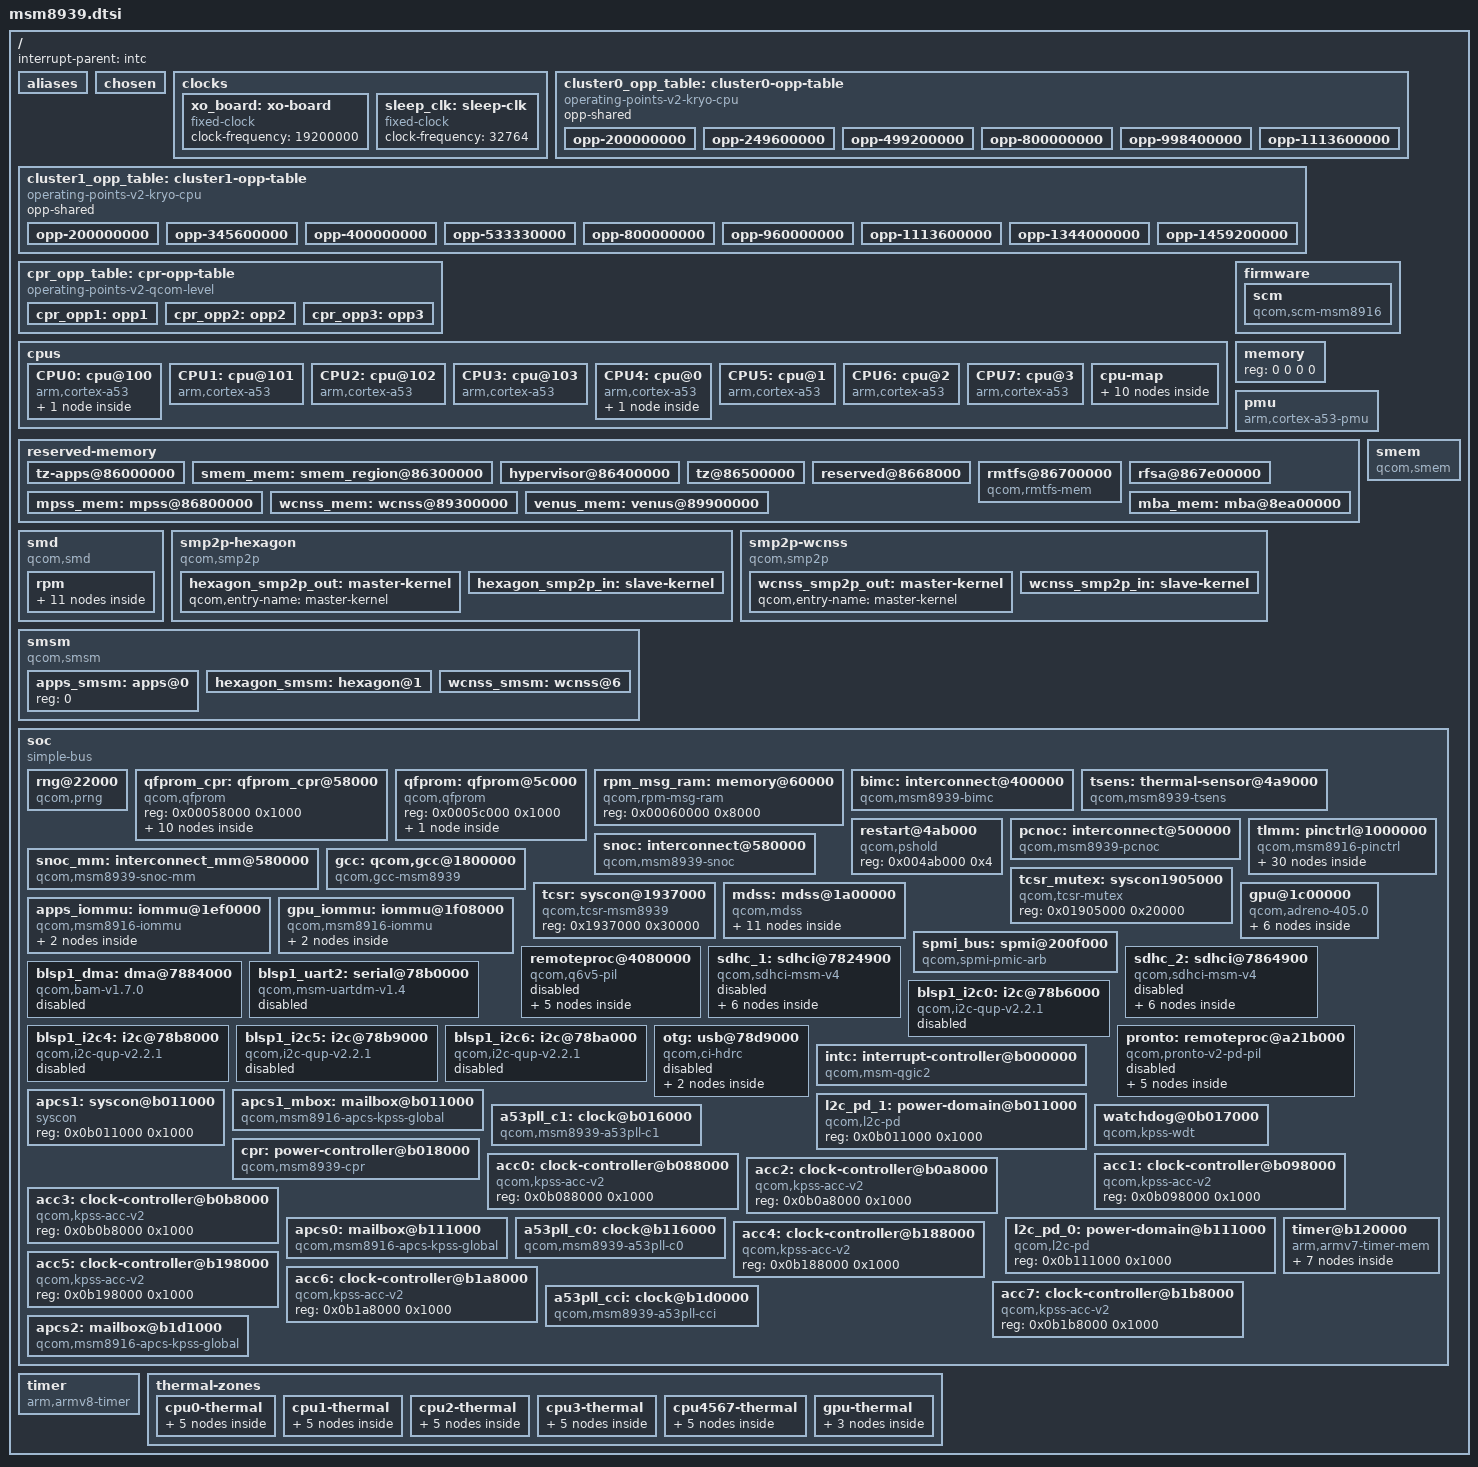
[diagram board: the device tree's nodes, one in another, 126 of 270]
// SPDX-License-Identifier: GPL-2.0
/*
 * MSM8939 SoC device tree source
 *
 * Copyright (c) 2020, Pavel Dubrova <pashadubrova@gmail.com>
 */

#include <dt-bindings/interconnect/qcom,msm8939.h>
#include <dt-bindings/interrupt-controller/arm-gic.h>
#include <dt-bindings/thermal/thermal.h>
#include <dt-bindings/clock/qcom,gcc-msm8939.h>
#include <dt-bindings/clock/qcom,rpmcc.h>
#include <dt-bindings/power/qcom-rpmpd.h>
#include <dt-bindings/reset/qcom,gcc-msm8939.h>

/ {
	interrupt-parent = <&intc>;

	#address-cells = <2>;
	#size-cells = <2>;

	aliases {
		sdhc1 = &sdhc_1; /* SDC1 eMMC slot */
		sdhc2 = &sdhc_2; /* SDC2 SD card slot */
	};

	chosen { };

	clocks {
		xo_board: xo-board {
			compatible = "fixed-clock";
			#clock-cells = <0>;
			clock-frequency = <19200000>;
		};

		sleep_clk: sleep-clk {
			compatible = "fixed-clock";
			#clock-cells = <0>;
			clock-frequency = <32764>;
		};
	};

	cluster0_opp_table: cluster0-opp-table {
		compatible = "operating-points-v2-kryo-cpu";
		opp-shared;

		opp-200000000 {
			opp-hz = /bits/ 64 <200000000>;
			required-opps = <&cpr_opp1>;
		};

		opp-249600000 {
			opp-hz = /bits/ 64 <249600000>;
			required-opps = <&cpr_opp1>;
		};

		opp-499200000 {
			opp-hz = /bits/ 64 <499200000>;
			required-opps = <&cpr_opp2>;
		};

		opp-800000000 {
			opp-hz = /bits/ 64 <800000000>;
			required-opps = <&cpr_opp2>;
		};

		opp-998400000 {
			opp-hz = /bits/ 64 <998400000>;
			required-opps = <&cpr_opp3>;
		};

		opp-1113600000 {
			opp-hz = /bits/ 64 <1113600000>;
			required-opps = <&cpr_opp3>;
		};
	};

	cluster1_opp_table: cluster1-opp-table {
		compatible = "operating-points-v2-kryo-cpu";
		opp-shared;

		opp-200000000 {
			opp-hz = /bits/ 64 <200000000>;
			required-opps = <&cpr_opp1>;
		};

		opp-345600000 {
			opp-hz = /bits/ 64 <345600000>;
			required-opps = <&cpr_opp1>;
		};

		opp-400000000 {
			opp-hz = /bits/ 64 <400000000>;
			required-opps = <&cpr_opp1>;
		};

		opp-533330000 {
			opp-hz = /bits/ 64 <533330000>;
			required-opps = <&cpr_opp2>;
		};

		opp-800000000 {
			opp-hz = /bits/ 64 <800000000>;
			required-opps = <&cpr_opp2>;
		};

		opp-960000000 {
			opp-hz = /bits/ 64 <960000000>;
			required-opps = <&cpr_opp2>;
		};

		opp-1113600000 {
			opp-hz = /bits/ 64 <1113600000>;
			required-opps = <&cpr_opp2>;
		};

		opp-1344000000 {
			opp-hz = /bits/ 64 <1344000000>;
			required-opps = <&cpr_opp3>;
		};

		opp-1459200000 {
			opp-hz = /bits/ 64 <1459200000>;
			required-opps = <&cpr_opp3>;
		};
	};

	cpr_opp_table: cpr-opp-table {
		compatible = "operating-points-v2-qcom-level";

		cpr_opp1: opp1 {
			opp-level = <1>;
			qcom,opp-fuse-level = <1>;
		};
		cpr_opp2: opp2 {
			opp-level = <2>;
			qcom,opp-fuse-level = <2>;
		};
		cpr_opp3: opp3 {
			opp-level = <3>;
			qcom,opp-fuse-level = <3>;
		};
	};

	cpus {
		#address-cells = <1>;
		#size-cells = <0>;

		CPU0: cpu@100 {
			device_type = "cpu";
			compatible = "arm,cortex-a53";
			reg = <0x100>;
			next-level-cache = <&L2_1>;
			enable-method = "qcom,kpss-acc-v2";
			qcom,acc = <&acc0>;
			clocks = <&apcs1_mbox>;
			operating-points-v2 = <&cluster1_opp_table>;
			power-domains = <&cpr>;
			power-domain-names = "cpr";
			#cooling-cells = <2>;
			L2_1: l2-cache {
				compatible = "cache";
				cache-level = <2>;
				power-domain = <&l2c_pd_1>;
			};
		};

		CPU1: cpu@101 {
			device_type = "cpu";
			compatible = "arm,cortex-a53";
			reg = <0x101>;
			next-level-cache = <&L2_1>;
			enable-method = "qcom,kpss-acc-v2";
			qcom,acc = <&acc1>;
			clocks = <&apcs1_mbox>;
			operating-points-v2 = <&cluster1_opp_table>;
			power-domains = <&cpr>;
			power-domain-names = "cpr";
			#cooling-cells = <2>;
		};

		CPU2: cpu@102 {
			device_type = "cpu";
			compatible = "arm,cortex-a53";
			reg = <0x102>;
			next-level-cache = <&L2_1>;
			enable-method = "qcom,kpss-acc-v2";
			qcom,acc = <&acc2>;
			clocks = <&apcs1_mbox>;
			operating-points-v2 = <&cluster1_opp_table>;
			power-domains = <&cpr>;
			power-domain-names = "cpr";
			#cooling-cells = <2>;
		};

		CPU3: cpu@103 {
			device_type = "cpu";
			compatible = "arm,cortex-a53";
			reg = <0x103>;
			next-level-cache = <&L2_1>;
			enable-method = "qcom,kpss-acc-v2";
			qcom,acc = <&acc3>;
			clocks = <&apcs1_mbox>;
			operating-points-v2 = <&cluster1_opp_table>;
			power-domains = <&cpr>;
			power-domain-names = "cpr";
			#cooling-cells = <2>;
		};

		CPU4: cpu@0 {
			device_type = "cpu";
			compatible = "arm,cortex-a53";
			reg = <0x0>;
			next-level-cache = <&L2_0>;
			enable-method = "qcom,kpss-acc-v2";
			qcom,acc = <&acc4>;
			clocks = <&apcs0>;
			operating-points-v2 = <&cluster0_opp_table>;
			power-domains = <&cpr>;
			power-domain-names = "cpr";
			#cooling-cells = <2>;
			L2_0: l2-cache {
				compatible = "cache";
				cache-level = <2>;
				power-domain = <&l2c_pd_0>;
			};
		};

		CPU5: cpu@1 {
			device_type = "cpu";
			compatible = "arm,cortex-a53";
			reg = <0x1>;
			next-level-cache = <&L2_0>;
			enable-method = "qcom,kpss-acc-v2";
			qcom,acc = <&acc5>;
			clocks = <&apcs0>;
			operating-points-v2 = <&cluster0_opp_table>;
			power-domains = <&cpr>;
			power-domain-names = "cpr";
			#cooling-cells = <2>;
		};

		CPU6: cpu@2 {
			device_type = "cpu";
			compatible = "arm,cortex-a53";
			reg = <0x2>;
			next-level-cache = <&L2_0>;
			enable-method = "qcom,kpss-acc-v2";
			qcom,acc = <&acc6>;
			clocks = <&apcs0>;
			operating-points-v2 = <&cluster0_opp_table>;
			power-domains = <&cpr>;
			power-domain-names = "cpr";
			#cooling-cells = <2>;
		};

		CPU7: cpu@3 {
			device_type = "cpu";
			compatible = "arm,cortex-a53";
			reg = <0x3>;
			next-level-cache = <&L2_0>;
			enable-method = "qcom,kpss-acc-v2";
			qcom,acc = <&acc7>;
			clocks = <&apcs0>;
			operating-points-v2 = <&cluster0_opp_table>;
			power-domains = <&cpr>;
			power-domain-names = "cpr";
			#cooling-cells = <2>;
		};

		cpu-map {
			cluster0 {
				core0 {
					cpu = <&CPU4>;
				};

				core1 {
					cpu = <&CPU5>;
				};

				core2 {
					cpu = <&CPU6>;
				};

				core3 {
					cpu = <&CPU7>;
				};
			};

			cluster1 {
				core0 {
					cpu = <&CPU0>;
				};

				core1 {
					cpu = <&CPU1>;
				};

				core2 {
					cpu = <&CPU2>;
				};

				core3 {
					cpu = <&CPU3>;
				};
			};
		};
	};

	firmware {
		scm: scm {
			compatible = "qcom,scm-msm8916", "qcom,scm";
			clocks = <&gcc GCC_CRYPTO_CLK>,
				 <&gcc GCC_CRYPTO_AXI_CLK>,
				 <&gcc GCC_CRYPTO_AHB_CLK>;
			clock-names = "core", "bus", "iface";
			#reset-cells = <1>;
		};
	};

	memory {
		device_type = "memory";
		/* We expect the bootloader to fill in the reg */
		reg = <0 0 0 0>;
	};

	pmu {
		compatible = "arm,cortex-a53-pmu";
		interrupts = <GIC_PPI 7 (GIC_CPU_MASK_SIMPLE(4) | IRQ_TYPE_LEVEL_HIGH)>;
	};

	reserved-memory {
		#address-cells = <2>;
		#size-cells = <2>;
		ranges;

		tz-apps@86000000 {
			reg = <0x0 0x86000000 0x0 0x300000>;
			no-map;
		};

		smem_mem: smem_region@86300000 {
			reg = <0x0 0x86300000 0x0 0x100000>;
			no-map;
		};

		hypervisor@86400000 {
			reg = <0x0 0x86400000 0x0 0x100000>;
			no-map;
		};

		tz@86500000 {
			reg = <0x0 0x86500000 0x0 0x180000>;
			no-map;
		};

		reserved@8668000 {
			reg = <0x0 0x86680000 0x0 0x80000>;
			no-map;
		};

		rmtfs@86700000 {
			compatible = "qcom,rmtfs-mem";
			reg = <0x0 0x86700000 0x0 0xe0000>;
			no-map;

			qcom,client-id = <1>;
		};

		rfsa@867e00000 {
			reg = <0x0 0x867e0000 0x0 0x20000>;
			no-map;
		};

		mpss_mem: mpss@86800000 {
			reg = <0x0 0x86800000 0x0 0x2b00000>;
			no-map;
		};

		wcnss_mem: wcnss@89300000 {
			reg = <0x0 0x89300000 0x0 0x600000>;
			no-map;
		};

		venus_mem: venus@89900000 {
			reg = <0x0 0x89900000 0x0 0x600000>;
			no-map;
		};

		mba_mem: mba@8ea00000 {
			no-map;
			reg = <0 0x8ea00000 0 0x200000>;
		};
	};

	smd {
		compatible = "qcom,smd";

		rpm {
			interrupts = <GIC_SPI 168 IRQ_TYPE_EDGE_RISING>;
			qcom,ipc = <&apcs1 8 0>;
			qcom,smd-edge = <15>;

			rpm_requests: rpm-requests {
				compatible = "qcom,rpm-msm8936";
				qcom,smd-channels = "rpm_requests";

				interconnect-smd-rpm {
					compatible = "qcom,interconnect-smd-rpm";
				};

				rpmcc: clock-controller {
					compatible = "qcom,rpmcc-msm8936";
					#clock-cells = <1>;
				};

				rpmpd: power-controller {
					compatible = "qcom,msm8939-rpmpd";
					#power-domain-cells = <1>;
					operating-points-v2 = <&rpmpd_opp_table>;

					rpmpd_opp_table: opp-table {
						compatible = "operating-points-v2";

						rpmpd_opp_ret: opp1 {
							opp-level = <1>;
						};

						rpmpd_opp_svs_krait: opp2 {
							opp-level = <2>;
						};

						rpmpd_opp_svs_soc: opp3 {
							opp-level = <3>;
						};

						rpmpd_opp_nom: opp4 {
							opp-level = <4>;
						};

						rpmpd_opp_turbo: opp5 {
							opp-level = <5>;
						};

						rpmpd_opp_super_turbo: opp6 {
							opp-level = <6>;
						};
					};
				};
			};
		};
	};

	smem {
		compatible = "qcom,smem";
		memory-region = <&smem_mem>;
		qcom,rpm-msg-ram = <&rpm_msg_ram>;
		hwlocks = <&tcsr_mutex 3>;
	};

	smp2p-hexagon {
		compatible = "qcom,smp2p";
		qcom,smem = <435>, <428>;

		interrupts = <GIC_SPI 27 IRQ_TYPE_EDGE_RISING>;

		mboxes = <&apcs1_mbox 14>;

		qcom,local-pid = <0>;
		qcom,remote-pid = <1>;

		hexagon_smp2p_out: master-kernel {
			qcom,entry-name = "master-kernel";

			#qcom,smem-state-cells = <1>;
		};

		hexagon_smp2p_in: slave-kernel {
			qcom,entry-name = "slave-kernel";

			interrupt-controller;
			#interrupt-cells = <2>;
		};
	};

	smp2p-wcnss {
		compatible = "qcom,smp2p";
		qcom,smem = <451>, <431>;

		interrupts = <GIC_SPI 143 IRQ_TYPE_EDGE_RISING>;

		mboxes = <&apcs1_mbox 18>;

		qcom,local-pid = <0>;
		qcom,remote-pid = <4>;

		wcnss_smp2p_out: master-kernel {
			qcom,entry-name = "master-kernel";

			#qcom,smem-state-cells = <1>;
		};

		wcnss_smp2p_in: slave-kernel {
			qcom,entry-name = "slave-kernel";

			interrupt-controller;
			#interrupt-cells = <2>;
		};
	};

	smsm {
		compatible = "qcom,smsm";

		#address-cells = <1>;
		#size-cells = <0>;

		qcom,ipc-1 = <&apcs1 8 13>;
		qcom,ipc-3 = <&apcs1 8 19>;

		apps_smsm: apps@0 {
			reg = <0>;

			#qcom,smem-state-cells = <1>;
		};

		hexagon_smsm: hexagon@1 {
			reg = <1>;
			interrupts = <GIC_SPI 26 IRQ_TYPE_EDGE_RISING>;

			interrupt-controller;
			#interrupt-cells = <2>;
		};

		wcnss_smsm: wcnss@6 {
			reg = <6>;
			interrupts = <GIC_SPI 144 IRQ_TYPE_EDGE_RISING>;

			interrupt-controller;
			#interrupt-cells = <2>;
		};
	};

	soc: soc {
		#address-cells = <1>;
		#size-cells = <1>;
		ranges = <0 0 0 0xffffffff>;
		compatible = "simple-bus";

		rng@22000 {
			compatible = "qcom,prng";
			reg = <0x00022000 0x200>;
			clocks = <&gcc GCC_PRNG_AHB_CLK>;
			clock-names = "core";

			interconnects = <&bimc MASTER_AMPSS_M0 &pcnoc SLAVE_PRNG>;
			interconnect-names = "cpu";
		};

		qfprom_cpr: qfprom_cpr@58000 {
			compatible = "qcom,qfprom";
			reg = <0x00058000 0x1000>;

			#address-cells = <1>;
			#size-cells = <1>;

			cpr_efuse_init_voltage1: ivoltage1@dc {
				reg = <0xdc 0x4>;
				bits = <4 6>;
			};

			cpr_efuse_init_voltage2: ivoltage2@da {
				reg = <0xda 0x4>;
				bits = <2 6>;
			};

			cpr_efuse_init_voltage3: ivoltage3@d8 {
				reg = <0xd8 0x4>;
				bits = <0 6>;
			};

			cpr_efuse_quot1: quot1@dc {
				reg = <0xdc 0x4>;
				bits = <10 12>;
			};

			cpr_efuse_quot2: quot2@da {
				reg = <0xda 0x4>;
				bits = <2 12>;
			};

			cpr_efuse_quot3: quot3@d8 {
				reg = <0xd8 0x4>;
				bits = <2 12>;
			};

			cpr_efuse_ring1: ring1@de {
				reg = <0xde 0x4>;
				bits = <6 3>;
			};

			cpr_efuse_ring2: ring2@de {
				reg = <0xde 0x4>;
				bits = <6 3>;
			};

			cpr_efuse_ring3: ring3@de {
				reg = <0xde 0x4>;
				bits = <6 3>;
			};

			cpr_efuse_revision: revision@40 {
				/* This info is missing. Not used neither. */
				reg = <0x40 0x4>;
				bits = <3 2>;
			};
		};

		qfprom: qfprom@5c000 {
			compatible = "qcom,qfprom";
			reg = <0x0005c000 0x1000>;
			#address-cells = <1>;
			#size-cells = <1>;
			tsens_caldata: caldata@d0 {
				reg = <0xa0 0x5c>;
			};
		};

		rpm_msg_ram: memory@60000 {
			compatible = "qcom,rpm-msg-ram";
			reg = <0x00060000 0x8000>;
		};

		bimc: interconnect@400000 {
			compatible = "qcom,msm8939-bimc";
			reg = <0x00400000 0x62000>;

			clocks = <&rpmcc RPM_SMD_BIMC_CLK>,
				 <&rpmcc RPM_SMD_BIMC_A_CLK>;
			clock-names = "bus", "bus_a";

			#interconnect-cells = <1>;
		};

		tsens: thermal-sensor@4a9000 {
			compatible = "qcom,msm8939-tsens";
			reg = <0x004a9000 0x1000>,
			      <0x004a8000 0x1000>;
			nvmem-cells = <&tsens_caldata>;
			nvmem-cell-names = "calib";
			interrupts = <GIC_SPI 184 IRQ_TYPE_LEVEL_HIGH>;
			interrupt-names = "uplow";
			#qcom,sensors = <10>;
			#thermal-sensor-cells = <1>;
		};

		restart@4ab000 {
			compatible = "qcom,pshold";
			reg = <0x004ab000 0x4>;
		};

		pcnoc: interconnect@500000 {
			compatible = "qcom,msm8939-pcnoc";
			reg = <0x00500000 0x11000>;

			clocks = <&rpmcc RPM_SMD_PCNOC_CLK>,
				 <&rpmcc RPM_SMD_PCNOC_A_CLK>;
			clock-names = "bus", "bus_a";

			#interconnect-cells = <1>;
		};

		snoc: interconnect@580000 {
			compatible = "qcom,msm8939-snoc";
			reg = <0x580000 0x14080>;

			clocks = <&rpmcc RPM_SMD_SNOC_CLK>,
				 <&rpmcc RPM_SMD_SNOC_A_CLK>;
			clock-names = "bus", "bus_a";

			#interconnect-cells = <1>;
		};

		snoc_mm: interconnect_mm@580000 {
			compatible = "qcom,msm8939-snoc-mm";
			reg = <0x580000 0x14080>;

			clocks = <&rpmcc RPM_SMD_SYSMMNOC_CLK>,
				 <&rpmcc RPM_SMD_SYSMMNOC_A_CLK>;
			clock-names = "bus", "bus_a";

			#interconnect-cells = <1>;
		};

		tlmm: pinctrl@1000000 {
			compatible = "qcom,msm8916-pinctrl";
			reg = <0x01000000 0x300000>;
			interrupts = <GIC_SPI 208 IRQ_TYPE_LEVEL_HIGH>;
			gpio-controller;
			gpio-ranges = <&tlmm 0 0 122>;
			#gpio-cells = <2>;
			interrupt-controller;
			#interrupt-cells = <2>;

			blsp1_uart2_default: blsp1-uart2-default {
				pins = "gpio4", "gpio5";
				function = "blsp_uart2";

				drive-strength = <16>;
				bias-disable;
			};

			blsp1_uart2_sleep: blsp1-uart2-sleep {
				pins = "gpio4", "gpio5";
				function = "gpio";

				drive-strength = <2>;
				bias-pull-down;
			};

			blsp1_i2c0_default: blsp1-i2c0-default {
				pins = "gpio6", "gpio7";
				function = "blsp_i2c2";

				drive-strength = <2>;
				bias-disable;
			};

			blsp1_i2c0_sleep: blsp1-i2c0-sleep {
				pins = "gpio6", "gpio7";
				function = "gpio";

				drive-strength = <2>;
				bias-disable;
			};

			ts_reset_default: ts-reset-default {
				pins = "gpio12";
				function = "gpio";

				driver-strength = <16>;
				bias-pull-up;
			};

			ts_reset_sleep: ts-reset-sleep {
				pins = "gpio12";
				function = "gpio";

				driver-strength = <2>;
				bias-pull-down;
			};

			ts_int_default: ts-int-default {
				pins = "gpio13";
				function = "gpio";

				driver-strength = <16>;
				bias-pull-up;
			};

			ts_int_sleep: ts-int-sleep {
				pins = "gpio13";
				function = "gpio";

				driver-strength = <2>;
				bias-pull-down;
			};

			blsp1_i2c4_default: blsp1-i2c4-default {
				pins = "gpio14", "gpio15";
				function = "blsp_i2c4";

				drive-strength = <2>;
				bias-disable;
			};

			blsp1_i2c4_sleep: blsp1-i2c4-sleep {
				pins = "gpio14", "gpio15";
				function = "gpio";

				drive-strength = <2>;
				bias-disable;
			};

			blsp1_i2c5_default: blsp1-i2c5-default {
				pins = "gpio18", "gpio19";
				function = "blsp_i2c5";

				drive-strength = <2>;
				bias-disable;
			};

			blsp1_i2c5_sleep: blsp1-i2c5-sleep {
				pins = "gpio18", "gpio19";
				function = "gpio";

				drive-strength = <2>;
				bias-disable;
			};

			blsp1_i2c6_default: blsp1-i2c6-default {
				pins = "gpio22", "gpio23";
				function = "blsp_i2c6";

				drive-strength = <2>;
				bias-disable;
			};

			blsp1_i2c6_sleep: blsp1-i2c6-sleep {
				pins = "gpio22", "gpio23";
				function = "gpio";

				drive-strength = <2>;
				bias-disable;
			};

			sdc2_cd_on: sdc2-cd-on {
				pins = "gpio38";
				function = "gpio";

				drive-strength = <2>;
				bias-pull-up;
			};

			sdc2_cd_off: sdc2-cd-off {
				pins = "gpio38";
				function = "gpio";

				drive-strength = <2>;
				bias-disable;
			};

			usb_id_default: usb-id-default {
				pins = "gpio110";
				function = "gpio";

				drive-strength = <8>;
				bias-pull-up;
			};

			wcnss_default: wcnss-active {
				pins = "gpio40", "gpio41", "gpio42", "gpio43", "gpio44";
				function = "wcss_wlan";

				drive-strength = <6>;
				bias-pull-up;
			};

			sdc1_clk_on: sdc1-clk-on {
				pins = "sdc1_clk";

				drive-strength = <16>;
				bias-disable;
			};

			sdc1_clk_off: sdc1-clk-off {
				pins = "sdc1_clk";

				drive-strength = <2>;
				bias-disable;
			};

			sdc1_cmd_on: sdc1-cmd-on {
				pins = "sdc1_cmd";

				drive-strength = <10>;
				bias-pull-up;
			};

			sdc1_cmd_off: sdc1-cmd-off {
				pins = "sdc1_cmd";

				drive-strength = <2>;
				bias-pull-up;
			};

			sdc1_data_on: sdc1-data-on {
				pins = "sdc1_data";

				drive-strength = <10>;
				bias-pull-up;
			};

			sdc1_data_off: sdc1-data-off {
				pins = "sdc1_data";

				drive-strength = <2>;
				bias-pull-up;
			};

			sdc2_clk_on: sdc2-clk-on {
				pins = "sdc2_clk";

				drive-strength = <16>;
				bias-disable;
			};

			sdc2_clk_off: sdc2-clk-off {
				pins = "sdc2_clk";

				drive-strength = <2>;
				bias-disable;
			};

			sdc2_cmd_on: sdc2-cmd-on {
				pins = "sdc2_cmd";

				drive-strength = <10>;
				bias-pull-up;
			};

			sdc2_cmd_off: sdc2-cmd-off {
				pins = "sdc2_cmd";

				drive-strength = <2>;
				bias-pull-up;
			};

			sdc2_data_on: sdc2-data-on {
				pins = "sdc2_data";

				drive-strength = <10>;
				bias-pull-up;
			};

			sdc2_data_off: sdc2-data-off {
				pins = "sdc2_data";

				drive-strength = <2>;
				bias-pull-up;
			};
		};

		gcc: qcom,gcc@1800000 {
			compatible = "qcom,gcc-msm8939";
			reg = <0x01800000 0x80000>;
			clock-names = "xo", "sleep_clk";
			clocks = <&xo_board>, <&sleep_clk>;
			#clock-cells = <1>;
			#reset-cells = <1>;
			power-domains = <&rpmpd MSM8939_VDDCX>;
			power-domain-names = "dig";
			#power-domain-cells = <1>;
		};

		tcsr_mutex: syscon1905000 {
			compatible = "qcom,tcsr-mutex", "syscon";
			reg = <0x01905000 0x20000>;

			#hwlock-cells = <1>;
		};

		tcsr: syscon@1937000 {
			compatible = "qcom,tcsr-msm8939", "syscon";
			reg = <0x1937000 0x30000>;
		};

		mdss: mdss@1a00000 {
			compatible = "qcom,mdss";
			reg = <0x01a00000 0x1000>,
			      <0x01ac8000 0x3000>;
			reg-names = "mdss_phys", "vbif_phys";

			power-domains = <&gcc MDSS_GDSC>;

			clocks = <&gcc GCC_MDSS_AHB_CLK>,
				 <&gcc GCC_MDSS_AXI_CLK>,
				 <&gcc GCC_MDSS_VSYNC_CLK>;
			clock-names = "iface", "bus", "vsync";

			interrupts = <GIC_SPI 72 IRQ_TYPE_LEVEL_HIGH>;
			interrupt-controller;
			#interrupt-cells = <1>;

			#address-cells = <1>;
			#size-cells = <1>;
			ranges;

			mdp: mdp@1a01000 {
				compatible = "qcom,mdp5";
				reg = <0x01a01000 0x89000>;
				reg-names = "mdp_phys";

				interrupt-parent = <&mdss>;
				interrupts = <IRQ_TYPE_NONE>;

				clocks = <&gcc GCC_MDSS_AHB_CLK>,
					 <&gcc GCC_MDSS_AXI_CLK>,
					 <&gcc GCC_MDSS_MDP_CLK>,
					 <&gcc GCC_MDSS_VSYNC_CLK>,
					 <&gcc GCC_MDP_TBU_CLK>,
					 <&gcc GCC_MDP_RT_TBU_CLK>;
				clock-names = "iface",
					      "bus",
					      "core",
					      "vsync",
					      "tbu",
					      "tbu_rt";

				iommus = <&apps_iommu 4>;

				interconnects = <&snoc_mm MASTER_MDP_PORT0 &bimc SLAVE_EBI_CH0>;
				interconnect-names = "mdp0-mem";

				ports {
					#address-cells = <1>;
					#size-cells = <0>;

					port@0 {
						reg = <0>;

						mdp5_intf1_out: endpoint {
							remote-endpoint = <&dsi0_in>;
						};
					};
				};
			};

			dsi0: dsi@1a98000 {
				compatible = "qcom,mdss-dsi-ctrl";
				reg = <0x01a98000 0x25c>;
				reg-names = "dsi_ctrl";

				interrupt-parent = <&mdss>;
				interrupts = <IRQ_TYPE_LEVEL_HIGH>;

				assigned-clocks = <&gcc BYTE0_CLK_SRC>,
						  <&gcc PCLK0_CLK_SRC>;
				assigned-clock-parents = <&dsi_phy0 0>,
							 <&dsi_phy0 1>;

				clocks = <&gcc GCC_MDSS_MDP_CLK>,
					 <&gcc GCC_MDSS_AHB_CLK>,
					 <&gcc GCC_MDSS_AXI_CLK>,
					 <&gcc GCC_MDSS_BYTE0_CLK>,
					 <&gcc GCC_MDSS_PCLK0_CLK>,
					 <&gcc GCC_MDSS_ESC0_CLK>;
				clock-names = "mdp_core",
					      "iface",
					      "bus",
					      "byte",
					      "pixel",
					      "core";

				phys = <&dsi_phy0>;
				phy-names = "dsi-phy";

				#address-cells = <1>;
				#size-cells = <0>;

				ports {
					#address-cells = <1>;
					#size-cells = <0>;

					port@0 {
						reg = <0>;
						dsi0_in: endpoint {
							remote-endpoint = <&mdp5_intf1_out>;
						};
					};

					port@1 {
						reg = <1>;
						dsi0_out: endpoint {
						};
					};
				};
			};

			dsi_phy0: dsi-phy@1a98300 {
				compatible = "qcom,dsi-phy-28nm-lp";
				reg = <0x01a98300 0xd4>,
				      <0x01a98500 0x280>,
				      <0x01a98780 0x30>;
				reg-names = "dsi_pll",
					    "dsi_phy",
					    "dsi_phy_regulator";

				clocks = <&gcc GCC_MDSS_AHB_CLK>,
					 <&xo_board>;
				clock-names = "iface", "ref";

				qcom,dsi-phy-regulator-ldo-mode;

				#clock-cells = <1>;
				#phy-cells = <0>;
			};
		};

		gpu@1c00000 {
			compatible = "qcom,adreno-405.0", "qcom,adreno";
			reg = <0x01c00000 0x20000>;
			reg-names = "kgsl_3d0_reg_memory";
			interrupts = <GIC_SPI 33 IRQ_TYPE_LEVEL_HIGH>;
			interrupt-names = "kgsl_3d0_irq";

			clocks = <&gcc GCC_OXILI_GFX3D_CLK>,
				 <&gcc GCC_OXILI_AHB_CLK>,
				 <&gcc GCC_OXILI_GMEM_CLK>,
				 <&gcc GCC_BIMC_GFX_CLK>,
				 <&gcc GCC_BIMC_GPU_CLK>,
				 <&gcc GCC_GFX_TCU_CLK>,
				 <&gcc GCC_GFX_TBU_CLK>,
				 <&gcc GCC_OXILI_TIMER_CLK>;
			clock-names = "core",
				      "iface",
				      "mem",
				      "mem_iface",
				      "alt_mem_iface",
				      "gtcu",
				      "gtbu",
				      "rbbmtimer";

			iommus = <&gpu_iommu 1>, <&gpu_iommu 2>;

			interconnects = <&bimc MASTER_GRAPHICS_3D &bimc SLAVE_EBI_CH0>;
			interconnect-names = "gfx-mem";

			power-domains = <&gcc OXILI_GDSC>;
			operating-points-v2 = <&gpu_opp_table>;

			gpu_opp_table: opp-table {
				compatible = "operating-points-v2";

				opp-19200000 {
					opp-hz = /bits/ 64 <19200000>;
					opp-peak-kBps = <0>;
				};

				opp-220000000 {
					opp-hz = /bits/ 64 <220000000>;
					opp-peak-kBps = <2764000>;
				};

				opp-400000000 {
					opp-hz = /bits/ 64 <400000000>;
					opp-peak-kBps = <5600000>;
				};

				opp-465000000 {
					opp-hz = /bits/ 64 <465000000>;
					opp-peak-kBps = <5984000>;
				};

				opp-550000000 {
					opp-hz = /bits/ 64 <550000000>;
					opp-peak-kBps = <6368000>;
				};
			};
		};

		apps_iommu: iommu@1ef0000 {
			compatible = "qcom,msm8916-iommu", "qcom,msm-iommu-v1";
			reg = <0x1ef0000 0x3000>;
			ranges = <0 0x1e20000 0x40000>;

			clocks = <&gcc GCC_SMMU_CFG_CLK>,
				 <&gcc GCC_APSS_TCU_CLK>;
			clock-names = "iface", "bus";

			qcom,iommu-secure-id = <17>;

			#address-cells = <1>;
			#size-cells = <1>;
			#iommu-cells = <1>;

			// vfe:
			iommu-ctx@3000 {
				compatible = "qcom,msm-iommu-v1-sec";
				reg = <0x3000 0x1000>;
				interrupts = <GIC_SPI 54 IRQ_TYPE_LEVEL_HIGH>;
			};

			/* mdp_0 */
			iommu-ctx@4000 {
				compatible = "qcom,msm-iommu-v1-ns";
				reg = <0x4000 0x1000>;
				interrupts = <GIC_SPI 58 IRQ_TYPE_LEVEL_HIGH>;
			};
		};

		gpu_iommu: iommu@1f08000 {
			compatible = "qcom,msm8916-iommu", "qcom,msm-iommu-v1";
			ranges = <0 0x01f08000 0x10000>;

			clocks = <&gcc GCC_SMMU_CFG_CLK>,
				 <&gcc GCC_GFX_TCU_CLK>;
			clock-names = "iface", "bus";

			qcom,iommu-secure-id = <18>;

			power-domains = <&gcc OXILI_GDSC>;

			#address-cells = <1>;
			#size-cells = <1>;
			#iommu-cells = <1>;

			/* gfx3d_user */
			iommu-ctx@1000 {
				compatible = "qcom,msm-iommu-v1-ns";
				reg = <0x1000 0x1000>;
				interrupts = <GIC_SPI 241 IRQ_TYPE_LEVEL_HIGH>;
			};

			/* gfx3d_priv */
			iommu-ctx@2000 {
				compatible = "qcom,msm-iommu-v1-ns";
				reg = <0x2000 0x1000>;
				interrupts = <GIC_SPI 242 IRQ_TYPE_LEVEL_HIGH>;
			};
		};


		spmi_bus: spmi@200f000 {
			compatible = "qcom,spmi-pmic-arb";
			reg = <0x0200f000 0x001000>,
			      <0x02400000 0x400000>,
			      <0x02c00000 0x400000>,
			      <0x03800000 0x200000>,
			      <0x0200a000 0x002100>;
			reg-names = "core", "chnls", "obsrvr", "intr", "cnfg";

			interrupt-names = "periph_irq";
			interrupts = <GIC_SPI 190 IRQ_TYPE_LEVEL_HIGH>;

			qcom,ee = <0>;
			qcom,channel = <0>;
			#address-cells = <2>;
			#size-cells = <0>;
			interrupt-controller;
			#interrupt-cells = <4>;
		};

		remoteproc@4080000 {
			compatible = "qcom,q6v5-pil";
			reg = <0x04080000 0x100>,
			      <0x04020000 0x040>;

			reg-names = "qdsp6", "rmb";

			interrupts-extended = <&intc GIC_SPI 24 IRQ_TYPE_EDGE_RISING>,
					      <&hexagon_smp2p_in 0 IRQ_TYPE_EDGE_RISING>,
					      <&hexagon_smp2p_in 1 IRQ_TYPE_EDGE_RISING>,
					      <&hexagon_smp2p_in 2 IRQ_TYPE_EDGE_RISING>,
					      <&hexagon_smp2p_in 3 IRQ_TYPE_EDGE_RISING>;
			interrupt-names = "wdog", "fatal", "ready",
					  "handover", "stop-ack";

			clocks = <&gcc GCC_MSS_CFG_AHB_CLK>,
				 <&gcc GCC_MSS_Q6_BIMC_AXI_CLK>,
				 <&gcc GCC_BOOT_ROM_AHB_CLK>,
				 <&xo_board>;
			clock-names = "iface", "bus", "mem", "xo";

			qcom,smem-states = <&hexagon_smp2p_out 0>;
			qcom,smem-state-names = "stop";

			resets = <&scm 0>;
			reset-names = "mss_restart";

			cx-supply = <&pm8916_s1>;
			mx-supply = <&pm8916_l3>;
			pll-supply = <&pm8916_l7>;

			qcom,halt-regs = <&tcsr 0x18000 0x19000 0x1a000>;

			status = "disabled";

			mba {
				memory-region = <&mba_mem>;
			};

			mpss {
				memory-region = <&mpss_mem>;
			};

			smd-edge {
				interrupts = <GIC_SPI 25 IRQ_TYPE_EDGE_RISING>;

				qcom,smd-edge = <0>;
				mboxes = <&apcs1_mbox 12>;
				qcom,remote-pid = <1>;

				label = "hexagon";

				fastrpc {
					compatible = "qcom,fastrpc";
					qcom,smd-channels = "fastrpcsmd-apps-dsp";
					label = "adsp";

					#address-cells = <1>;
					#size-cells = <0>;

					cb@1{
						compatible = "qcom,fastrpc-compute-cb";
						reg = <1>;
					};
				};
			};
		};

		sdhc_1: sdhci@7824900 {
			compatible = "qcom,sdhci-msm-v4";
			reg = <0x07824900 0x11c>, <0x07824000 0x800>;
			reg-names = "hc_mem", "core_mem";

			interrupts = <GIC_SPI 123 IRQ_TYPE_LEVEL_HIGH>,
				     <GIC_SPI 138 IRQ_TYPE_LEVEL_HIGH>;
			interrupt-names = "hc_irq", "pwr_irq";

			clocks = <&gcc GCC_SDCC1_AHB_CLK>,
				 <&gcc GCC_SDCC1_APPS_CLK>,
				 <&xo_board>;
			clock-names = "iface", "core", "xo";

			bus-width = <8>;
			mmc-hs200-1_8v;
			mmc-ddr-1_8v;
			non-removable;

			pinctrl-names = "default", "sleep";
			pinctrl-0 = <&sdc1_clk_on &sdc1_cmd_on &sdc1_data_on>;
			pinctrl-1 = <&sdc1_clk_off &sdc1_cmd_off &sdc1_data_off>;

			interconnects = <&pcnoc MASTER_SDCC_1 &bimc SLAVE_EBI_CH0>;
			interconnect-names = "sdhc-mem";

			operating-points-v2 = <&sdhc1_opp_table>;

			status = "disabled";

			sdhc1_opp_table: sdhc1-opp-table {
				compatible = "operating-points-v2";

				opp-400000 {
					opp-hz = /bits/ 64 <400000>;
					opp-peak-kBps = <3200>;
					opp-avg-kBps = <1600>;
				};

				opp-25000000 {
					opp-hz = /bits/ 64 <25000000>;
					opp-peak-kBps = <200000>;
					opp-avg-kBps = <100000>;
				};

				opp-50000000 {
					opp-hz = /bits/ 64 <50000000>;
					opp-peak-kBps = <400000>;
					opp-avg-kBps = <200000>;
				};

				opp-100000000 {
					opp-hz = /bits/ 64 <100000000>;
					opp-peak-kBps = <800000>;
					opp-avg-kBps = <400000>;
				};

				opp-200000000 {
					opp-hz = /bits/ 64 <200000000>;
					opp-peak-kBps = <800000>;
					opp-avg-kBps = <400000>;
				};
			};
		};

		sdhc_2: sdhci@7864900 {
			compatible = "qcom,sdhci-msm-v4";
			reg = <0x07864900 0x11c>, <0x07864000 0x800>;
			reg-names = "hc_mem", "core_mem";

			interrupts = <GIC_SPI 125 IRQ_TYPE_LEVEL_HIGH>,
				     <GIC_SPI 221 IRQ_TYPE_LEVEL_HIGH>;
			interrupt-names = "hc_irq", "pwr_irq";

			clocks = <&gcc GCC_SDCC2_AHB_CLK>,
				 <&gcc GCC_SDCC2_APPS_CLK>,
				 <&xo_board>;
			clock-names = "iface", "core", "xo";

			bus-width = <4>;

			pinctrl-names = "default", "sleep";
			pinctrl-0 = <&sdc2_clk_on &sdc2_cmd_on &sdc2_data_on &sdc2_cd_on>;
			pinctrl-1 = <&sdc2_clk_off &sdc2_cmd_off &sdc2_data_off &sdc2_cd_off>;

			interconnects = <&pcnoc MASTER_SDCC_2 &bimc SLAVE_EBI_CH0>;
			interconnect-names = "sdhc-mem";

			operating-points-v2 = <&sdhc2_opp_table>;

			status = "disabled";

			sdhc2_opp_table: sdhc2-opp-table {
				compatible = "operating-points-v2";

				opp-400000 {
					opp-hz = /bits/ 64 <400000>;
					opp-peak-kBps = <3200>;
					opp-avg-kBps = <1600>;
				};

				opp-25000000 {
					opp-hz = /bits/ 64 <25000000>;
					opp-peak-kBps = <200000>;
					opp-avg-kBps = <100000>;
				};

				opp-50000000 {
					opp-hz = /bits/ 64 <50000000>;
					opp-peak-kBps = <400000>;
					opp-avg-kBps = <200000>;
				};

				opp-100000000 {
					opp-hz = /bits/ 64 <100000000>;
					opp-peak-kBps = <800000>;
					opp-avg-kBps = <400000>;
				};

				opp-200000000 {
					opp-hz = /bits/ 64 <200000000>;
					opp-peak-kBps = <800000>;
					opp-avg-kBps = <400000>;
				};
			};
		};

		blsp1_dma: dma@7884000 {
			compatible = "qcom,bam-v1.7.0";
			reg = <0x07884000 0x23000>;
			interrupts = <GIC_SPI 238 IRQ_TYPE_LEVEL_HIGH>;

			clocks = <&gcc GCC_BLSP1_AHB_CLK>;
			clock-names = "bam_clk";

			#dma-cells = <1>;
			qcom,ee = <0>;

			status = "disabled";
		};

		blsp1_uart2: serial@78b0000 {
			compatible = "qcom,msm-uartdm-v1.4", "qcom,msm-uartdm";
			reg = <0x078b0000 0x200>;
			interrupts = <GIC_SPI 108 IRQ_TYPE_LEVEL_HIGH>;

			clocks = <&gcc GCC_BLSP1_UART2_APPS_CLK>,
				 <&gcc GCC_BLSP1_AHB_CLK>;
			clock-names = "core", "iface";

			pinctr-names = "default", "sleep";
			pinctrl-0 = <&blsp1_uart2_default>;
			pinctr-1 = <&blsp1_uart2_sleep>;

			status = "disabled";
		};

		blsp1_i2c0: i2c@78b6000 {
			compatible = "qcom,i2c-qup-v2.2.1";
			reg = <0x078b6000 0x600>;

			clocks = <&gcc GCC_BLSP1_AHB_CLK>,
				 <&gcc GCC_BLSP1_QUP2_I2C_APPS_CLK>;
			clock-names = "iface", "core";

			pinctrl-names = "default", "sleep";
			pinctrl-0 = <&blsp1_i2c0_default>;
			pinctrl-1 = <&blsp1_i2c0_sleep>;

			interrupts = <GIC_SPI 96 IRQ_TYPE_LEVEL_HIGH>;
			#address-cells = <1>;
			#size-cells = <0>;
			dmas = <&blsp1_dma 6>, <&blsp1_dma 7>;
			dma-names = "tx", "rx";

			interconnects = <&pcnoc MASTER_BLSP_1 &bimc SLAVE_EBI_CH0>;
			interconnect-names = "i2c-mem";

			status = "disabled";
		};

		blsp1_i2c4: i2c@78b8000 {
			compatible = "qcom,i2c-qup-v2.2.1";
			reg = <0x078b8000 0x1000>;

			clocks = <&gcc GCC_BLSP1_AHB_CLK>,
				 <&gcc GCC_BLSP1_QUP4_I2C_APPS_CLK>;
			clock-names = "iface", "core";

			pinctrl-names = "default", "sleep";
			pinctrl-0 = <&blsp1_i2c4_default>;
			pinctrl-1 = <&blsp1_i2c4_sleep>;

			interrupts = <GIC_SPI 98 IRQ_TYPE_LEVEL_HIGH>;
			#address-cells = <1>;
			#size-cells = <0>;
			dmas = <&blsp1_dma 10>, <&blsp1_dma 11>;
			dma-names = "tx", "rx";

			interconnects = <&pcnoc MASTER_BLSP_1 &bimc SLAVE_EBI_CH0>;
			interconnect-names = "i2c-mem";

			status = "disabled";
		};

		blsp1_i2c5: i2c@78b9000 {
			compatible = "qcom,i2c-qup-v2.2.1";
			reg = <0x078b9000 0x600>;

			clocks = <&gcc GCC_BLSP1_AHB_CLK>,
				 <&gcc GCC_BLSP1_QUP5_I2C_APPS_CLK>;
			clock-names = "iface", "core";

			pinctrl-names = "default", "sleep";
			pinctrl-0 = <&blsp1_i2c5_default>;
			pinctrl-1 = <&blsp1_i2c5_sleep>;

			interrupts = <GIC_SPI 99 IRQ_TYPE_LEVEL_HIGH>;
			#address-cells = <1>;
			#size-cells = <0>;
			dmas = <&blsp1_dma 12>, <&blsp1_dma 13>;
			dma-names = "tx", "rx";

			interconnects = <&pcnoc MASTER_BLSP_1 &bimc SLAVE_EBI_CH0>;
			interconnect-names = "i2c-mem";

			status = "disabled";
		};

		blsp1_i2c6: i2c@78ba000 {
			compatible = "qcom,i2c-qup-v2.2.1";
			reg = <0x078ba000 0x1000>;

			clocks = <&gcc GCC_BLSP1_AHB_CLK>,
				 <&gcc GCC_BLSP1_QUP6_I2C_APPS_CLK>;
			clock-names = "iface", "core";

			pinctrl-names = "default", "sleep";
			pinctrl-0 = <&blsp1_i2c6_default>;
			pinctrl-1 = <&blsp1_i2c6_sleep>;

			interrupts = <GIC_SPI 100 IRQ_TYPE_LEVEL_HIGH>;
			#address-cells = <1>;
			#size-cells = <0>;
			dmas = <&blsp1_dma 14>, <&blsp1_dma 15>;
			dma-names = "tx", "rx";

			interconnects = <&pcnoc MASTER_BLSP_1 &bimc SLAVE_EBI_CH0>;
			interconnect-names = "i2c-mem";

			status = "disabled";
		};

		otg: usb@78d9000 {
			compatible = "qcom,ci-hdrc";
			reg = <0x078d9000 0x200>,
			      <0x078d9200 0x200>;
			#reset-cells = <1>;

			interrupts = <GIC_SPI 134 IRQ_TYPE_LEVEL_HIGH>,
				     <GIC_SPI 140 IRQ_TYPE_LEVEL_HIGH>;
					 
			clocks = <&gcc GCC_USB_HS_AHB_CLK>,
				 <&gcc GCC_USB_HS_SYSTEM_CLK>;
			clock-names = "iface", "core";

			assigned-clocks = <&gcc GCC_USB_HS_SYSTEM_CLK>;
			assigned-clock-rates = <80000000>;


			v1p8-supply = <&pm8916_l7>;
			v3p3-supply = <&pm8916_l13>;

			resets = <&gcc GCC_USB_HS_BCR>;
			reset-names = "core";

			ahb-burst-config = <0x0>;
			dr_mode = "otg";
			phy_type = "ulpi";
			phy-names = "usb-phy";
			phys = <&usb_hs_phy>;

			hnp-disable;
			srp-disable;
			adp-disable;

			status = "disabled";

			ulpi {
				usb_hs_phy: phy {
					status = "okay";
					compatible = "qcom,usb-hs-phy-msm8916",
						     "qcom,usb-hs-phy";
					#phy-cells = <0>;
					clocks = <&xo_board>, <&gcc GCC_USB2A_PHY_SLEEP_CLK>;
					clock-names = "ref", "sleep";
					resets = <&gcc GCC_USB2A_PHY_BCR>, <&otg 0>;
					reset-names = "phy", "por";
					qcom,init-seq = /bits/ 8 <0x0 0x44
						0x1 0x6b 0x2 0x24 0x3 0x13>;

					interconnects = <&pcnoc MASTER_USB_HS1 &bimc SLAVE_EBI_CH0>;
					interconnect-names = "usb-mem";
				};
			};
		};

		pronto: remoteproc@a21b000 {
			compatible = "qcom,pronto-v2-pd-pil", "qcom,pronto";
			reg = <0x0a204000 0x2000>, <0x0a202000 0x1000>, <0x0a21b000 0x3000>;
			reg-names = "ccu", "dxe", "pmu";

			memory-region = <&wcnss_mem>;

			interrupts-extended = <&intc GIC_SPI 149 IRQ_TYPE_EDGE_RISING>,
					      <&wcnss_smp2p_in 0 IRQ_TYPE_EDGE_RISING>,
					      <&wcnss_smp2p_in 1 IRQ_TYPE_EDGE_RISING>,
					      <&wcnss_smp2p_in 2 IRQ_TYPE_EDGE_RISING>,
					      <&wcnss_smp2p_in 3 IRQ_TYPE_EDGE_RISING>;
			interrupt-names = "wdog", "fatal", "ready", "handover", "stop-ack";

			power-domains = <&rpmpd MSM8939_VDDCX>,
					<&rpmpd MSM8939_VDDMX_AO>;
			power-domain-names = "vddcx", "vddmx";
			vddpx-supply = <&pm8916_l7>;

			qcom,state = <&wcnss_smp2p_out 0>;
			qcom,state-names = "stop";

			pinctrl-names = "default";
			pinctrl-0 = <&wcnss_default>;

			status = "disabled";

			iris {
				compatible = "qcom,wcn3680";

				clocks = <&rpmcc RPM_SMD_RF_CLK2>;
				clock-names = "xo";

				vddxo-supply = <&pm8916_l7>;
				vddrfa-supply = <&pm8916_s3>;
				vddpa-supply = <&pm8916_l9>;
				vdddig-supply = <&pm8916_l5>;
			};

			smd-edge {
				interrupts = <GIC_SPI 142 1>;

				qcom,ipc = <&apcs1 8 17>;
				qcom,smd-edge = <6>;
				qcom,remote-pid = <4>;

				label = "pronto";

				wcnss {
					compatible = "qcom,wcnss";
					qcom,smd-channels = "WCNSS_CTRL";

					qcom,mmio = <&pronto>;

					bt {
						compatible = "qcom,wcnss-bt";
					};

					wifi {
						compatible = "qcom,wcnss-wlan";

						interrupts = <GIC_SPI 145 IRQ_TYPE_LEVEL_HIGH>,
							     <GIC_SPI 146 IRQ_TYPE_LEVEL_HIGH>;
						interrupt-names = "tx", "rx";

						qcom,smem-states = <&apps_smsm 10>, <&apps_smsm 9>;
						qcom,smem-state-names = "tx-enable", "tx-rings-empty";
					};
				};
			};
		};

		intc: interrupt-controller@b000000 {
			compatible = "qcom,msm-qgic2";
			reg = <0x0b000000 0x1000>,
			      <0x0b002000 0x1000>;
			#interrupt-cells = <3>;
			interrupt-controller;
		};

		apcs1: syscon@b011000 {
			compatible = "syscon";
			reg = <0x0b011000 0x1000>;
		};

		apcs1_mbox: mailbox@b011000 {
			compatible = "qcom,msm8916-apcs-kpss-global";
			reg = <0x0b011000 0x1000>;
			#mbox-cells = <1>;
			clocks = <&a53pll_c1>, <&gcc GPLL0_VOTE>, <&xo_board>;
			clock-names = "pll", "aux", "ref";
			#clock-cells = <0>;
			clock-output-names = "a53mux_c1";
			/* Set a nominal frequency on a53mux_cci */
			assigned-clocks = <&apcs2>;
			assigned-clock-rates = <297600000>;
		};

		l2c_pd_1: power-domain@b011000 {
			compatible = "qcom,l2c-pd";
			reg = <0x0b011000 0x1000>;
		};

		a53pll_c1: clock@b016000 {
			compatible = "qcom,msm8939-a53pll-c1";
			reg = <0x0b016000 0x40>;
			#clock-cells = <0>;
			power-domains = <&rpmpd MSM8939_VDDCX_AO>;
			power-domain-names = "dig";
			dig-supply = <&pm8916_l7>;
		};

		watchdog@0b017000 {
			compatible = "qcom,kpss-wdt";
			reg = <0x0b017000 0x1000>;
			clocks = <&sleep_clk>;
		};

		cpr: power-controller@b018000 {
			compatible = "qcom,msm8939-cpr", "qcom,cpr";
			reg = <0x0b018000 0x1000>;

			interrupts = <GIC_SPI 15 IRQ_TYPE_EDGE_RISING>;
			clocks = <&xo_board>;
			clock-names = "ref";

			power-domains = <&rpmpd MSM8939_VDDMX_AO>;
			#power-domain-cells = <0>;

			operating-points-v2 = <&cpr_opp_table>;
			acc-syscon = <&tcsr>;

			nvmem-cells = <&cpr_efuse_init_voltage1>,
				<&cpr_efuse_init_voltage2>,
				<&cpr_efuse_init_voltage3>,
				<&cpr_efuse_quot1>,
				<&cpr_efuse_quot2>,
				<&cpr_efuse_quot3>,
				<&cpr_efuse_ring1>,
				<&cpr_efuse_ring2>,
				<&cpr_efuse_ring3>,
				<&cpr_efuse_revision>;
			nvmem-cell-names = "cpr_init_voltage1",
				"cpr_init_voltage2",
				"cpr_init_voltage3",
				"cpr_quotient1",
				"cpr_quotient2",
				"cpr_quotient3",
				"cpr_ring_osc1",
				"cpr_ring_osc2",
				"cpr_ring_osc3",
				"cpr_fuse_revision";
		};

		acc0: clock-controller@b088000 {
			compatible = "qcom,kpss-acc-v2";
			reg = <0x0b088000 0x1000>;
		};

		acc1: clock-controller@b098000 {
			compatible = "qcom,kpss-acc-v2";
			reg = <0x0b098000 0x1000>;
		};

		acc2: clock-controller@b0a8000 {
			compatible = "qcom,kpss-acc-v2";
			reg = <0x0b0a8000 0x1000>;
		};

		acc3: clock-controller@b0b8000 {
			compatible = "qcom,kpss-acc-v2";
			reg = <0x0b0b8000 0x1000>;
		};

		apcs0: mailbox@b111000 {
			compatible = "qcom,msm8916-apcs-kpss-global", "syscon";
			reg = <0x0b111000 0x1000>;
			#mbox-cells = <1>;
			clocks = <&a53pll_c0>, <&gcc GPLL0_VOTE>, <&xo_board>;
			clock-names = "pll", "aux", "ref";
			#clock-cells = <0>;
			clock-output-names = "a53mux_c0";
		};

		l2c_pd_0: power-domain@b111000 {
			compatible = "qcom,l2c-pd";
			reg = <0x0b111000 0x1000>;
		};

		a53pll_c0: clock@b116000 {
			compatible = "qcom,msm8939-a53pll-c0";
			reg = <0x0b116000 0x40>;
			#clock-cells = <0>;
			power-domains = <&rpmpd MSM8939_VDDCX_AO>;
			power-domain-names = "dig";
			dig-supply = <&pm8916_l7>;
		};

		timer@b120000 {
			compatible = "arm,armv7-timer-mem";
			reg = <0x0b120000 0x1000>;
			#address-cells = <1>;
			#size-cells = <1>;
			ranges;
			clock-frequency = <19200000>;

			frame@b121000 {
				frame-number = <0>;
				interrupts = <GIC_SPI 8 IRQ_TYPE_LEVEL_HIGH>,
					     <GIC_SPI 7 IRQ_TYPE_LEVEL_HIGH>;
				reg = <0x0b121000 0x1000>,
				      <0x0b122000 0x1000>;
			};

			frame@b123000 {
				frame-number = <1>;
				interrupts = <GIC_SPI 9 IRQ_TYPE_LEVEL_HIGH>;
				reg = <0x0b123000 0x1000>;
				status = "disabled";
			};

			frame@b124000 {
				frame-number = <2>;
				interrupts = <GIC_SPI 10 IRQ_TYPE_LEVEL_HIGH>;
				reg = <0x0b124000 0x1000>;
				status = "disabled";
			};

			frame@b125000 {
				frame-number = <3>;
				interrupts = <GIC_SPI 11 IRQ_TYPE_LEVEL_HIGH>;
				reg = <0x0b125000 0x1000>;
				status = "disabled";
			};

			frame@b126000 {
				frame-number = <4>;
				interrupts = <GIC_SPI 12 IRQ_TYPE_LEVEL_HIGH>;
				reg = <0x0b126000 0x1000>;
				status = "disabled";
			};

			frame@b127000 {
				frame-number = <5>;
				interrupts = <GIC_SPI 13 IRQ_TYPE_LEVEL_HIGH>;
				reg = <0x0b127000 0x1000>;
				status = "disabled";
			};

			frame@b128000 {
				frame-number = <6>;
				interrupts = <GIC_SPI 14 IRQ_TYPE_LEVEL_HIGH>;
				reg = <0x0b128000 0x1000>;
				status = "disabled";
			};
		};

		acc4: clock-controller@b188000 {
			compatible = "qcom,kpss-acc-v2";
			reg = <0x0b188000 0x1000>;
		};

		acc5: clock-controller@b198000 {
			compatible = "qcom,kpss-acc-v2";
			reg = <0x0b198000 0x1000>;
		};

		acc6: clock-controller@b1a8000 {
			compatible = "qcom,kpss-acc-v2";
			reg = <0x0b1a8000 0x1000>;
		};

		acc7: clock-controller@b1b8000 {
			compatible = "qcom,kpss-acc-v2";
			reg = <0x0b1b8000 0x1000>;
		};

		a53pll_cci: clock@b1d0000 {
			compatible = "qcom,msm8939-a53pll-cci";
			reg = <0x0b1d0000 0x40>;
			#clock-cells = <0>;
			power-domains = <&rpmpd MSM8939_VDDCX_AO>;
			power-domain-names = "dig";
			dig-supply = <&pm8916_l7>;
		};

		apcs2: mailbox@b1d1000 {
			compatible = "qcom,msm8916-apcs-kpss-global", "syscon";
			reg = <0x0b1d1000 0x1000>;
			#mbox-cells = <1>;
			clocks = <&a53pll_cci>, <&gcc GPLL0_VOTE>, <&xo_board>;
			clock-names = "pll", "aux", "ref";
			#clock-cells = <0>;
			clock-output-names = "a53mux_cci";
		};
	};

	timer {
		compatible = "arm,armv8-timer";
		interrupts = <GIC_PPI 2 (GIC_CPU_MASK_SIMPLE(4) | IRQ_TYPE_LEVEL_LOW)>,
			     <GIC_PPI 3 (GIC_CPU_MASK_SIMPLE(4) | IRQ_TYPE_LEVEL_LOW)>,
			     <GIC_PPI 4 (GIC_CPU_MASK_SIMPLE(4) | IRQ_TYPE_LEVEL_LOW)>,
			     <GIC_PPI 1 (GIC_CPU_MASK_SIMPLE(4) | IRQ_TYPE_LEVEL_LOW)>;
	};

	thermal-zones {
		cpu0-thermal {
			polling-delay-passive = <250>;
			polling-delay = <1000>;

			thermal-sensors = <&tsens 5>;

			trips {
				cpu0_alert: trip0 {
					temperature = <75000>;
					hysteresis = <2000>;
					type = "passive";
				};

				cpu0_crit: trip1 {
					temperature = <110000>;
					hysteresis = <2000>;
					type = "critical";
				};
			};

			cooling-maps {
				map0 {
					trip = <&cpu0_alert>;
					cooling-device = <&CPU0 THERMAL_NO_LIMIT THERMAL_NO_LIMIT>,
							 <&CPU1 THERMAL_NO_LIMIT THERMAL_NO_LIMIT>,
							 <&CPU2 THERMAL_NO_LIMIT THERMAL_NO_LIMIT>,
							 <&CPU3 THERMAL_NO_LIMIT THERMAL_NO_LIMIT>;
				};
			};
		};

		cpu1-thermal {
			polling-delay-passive = <250>;
			polling-delay = <1000>;

			thermal-sensors = <&tsens 6>;

			trips {
				cpu1_alert: trip0 {
					temperature = <75000>;
					hysteresis = <2000>;
					type = "passive";
				};

				cpu1_crit: trip1 {
					temperature = <110000>;
					hysteresis = <2000>;
					type = "critical";
				};
			};

			cooling-maps {
				map0 {
					trip = <&cpu1_alert>;
					cooling-device = <&CPU0 THERMAL_NO_LIMIT THERMAL_NO_LIMIT>,
							 <&CPU1 THERMAL_NO_LIMIT THERMAL_NO_LIMIT>,
							 <&CPU2 THERMAL_NO_LIMIT THERMAL_NO_LIMIT>,
							 <&CPU3 THERMAL_NO_LIMIT THERMAL_NO_LIMIT>;
				};
			};
		};

		cpu2-thermal {
			polling-delay-passive = <250>;
			polling-delay = <1000>;

			thermal-sensors = <&tsens 7>;

			trips {
				cpu2_alert: trip0 {
					temperature = <75000>;
					hysteresis = <2000>;
					type = "passive";
				};

				cpu2_crit: trip1 {
					temperature = <110000>;
					hysteresis = <2000>;
					type = "critical";
				};
			};

			cooling-maps {
				map0 {
					trip = <&cpu2_alert>;
					cooling-device = <&CPU0 THERMAL_NO_LIMIT THERMAL_NO_LIMIT>,
							 <&CPU1 THERMAL_NO_LIMIT THERMAL_NO_LIMIT>,
							 <&CPU2 THERMAL_NO_LIMIT THERMAL_NO_LIMIT>,
							 <&CPU3 THERMAL_NO_LIMIT THERMAL_NO_LIMIT>;
				};
			};
		};

		cpu3-thermal {
			polling-delay-passive = <250>;
			polling-delay = <1000>;

			thermal-sensors = <&tsens 8>;

			trips {
				cpu3_alert: trip0 {
					temperature = <75000>;
					hysteresis = <2000>;
					type = "passive";
				};

				cpu3_crit: trip1 {
					temperature = <110000>;
					hysteresis = <2000>;
					type = "critical";
				};
			};

			cooling-maps {
				map0 {
					trip = <&cpu3_alert>;
					cooling-device = <&CPU0 THERMAL_NO_LIMIT THERMAL_NO_LIMIT>,
							 <&CPU1 THERMAL_NO_LIMIT THERMAL_NO_LIMIT>,
							 <&CPU2 THERMAL_NO_LIMIT THERMAL_NO_LIMIT>,
							 <&CPU3 THERMAL_NO_LIMIT THERMAL_NO_LIMIT>;
				};
			};
		};

		cpu4567-thermal {
			polling-delay-passive = <250>;
			polling-delay = <1000>;

			thermal-sensors = <&tsens 9>;

			trips {
				cpu4567_alert: trip0 {
					temperature = <75000>;
					hysteresis = <2000>;
					type = "passive";
				};

				cpu4567_crit: trip1 {
					temperature = <110000>;
					hysteresis = <2000>;
					type = "critical";
				};
			};

			cooling-maps {
				map0 {
					trip = <&cpu4567_alert>;
					cooling-device = <&CPU4 THERMAL_NO_LIMIT THERMAL_NO_LIMIT>,
							 <&CPU5 THERMAL_NO_LIMIT THERMAL_NO_LIMIT>,
							 <&CPU6 THERMAL_NO_LIMIT THERMAL_NO_LIMIT>,
							 <&CPU7 THERMAL_NO_LIMIT THERMAL_NO_LIMIT>;
				};
			};
		};

		gpu-thermal {
			polling-delay-passive = <250>;
			polling-delay = <1000>;

			thermal-sensors = <&tsens 3>;

			trips {
				gpu_alert0: trip-point0 {
					temperature = <75000>;
					hysteresis = <2000>;
					type = "passive";
				};

				gpu_crit: gpu_crit {
					temperature = <95000>;
					hysteresis = <2000>;
					type = "critical";
				};
			};
		};
	};
};
